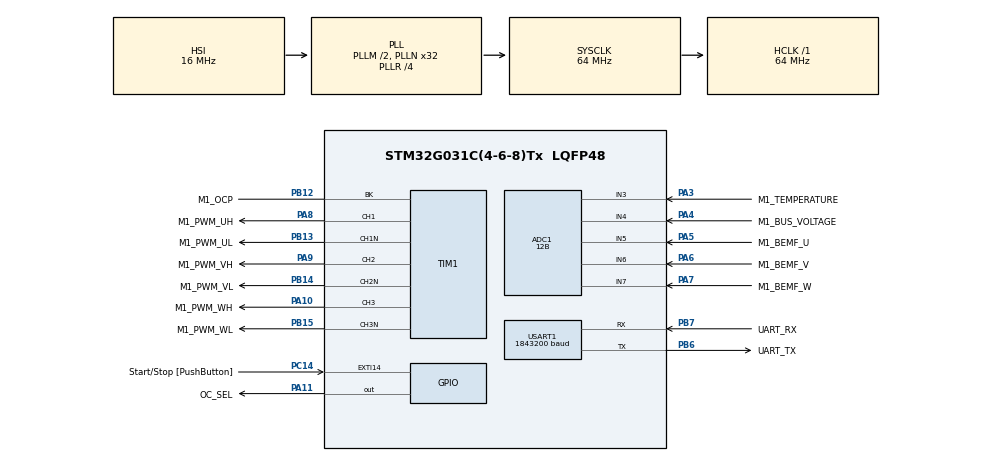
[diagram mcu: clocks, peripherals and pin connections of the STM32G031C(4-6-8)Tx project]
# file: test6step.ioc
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ADC1.ClockPrescaler=ADC_CLOCK_ASYNC_DIV1
ADC1.ContinuousConvMode=DISABLE
ADC1.DMAContinuousRequests=DISABLE
ADC1.DataAlign=ADC_DATAALIGN_LEFT
ADC1.DiscontinuousConvMode=DISABLE
ADC1.EOCSelection=ADC_EOC_SINGLE_CONV
ADC1.EnableAnalogWatchDog1=true
ADC1.ExternalTrigConv=ADC_EXTERNALTRIG_T1_TRGO2
ADC1.ExternalTrigConvEdge=ADC_EXTERNALTRIGCONVEDGE_FALLING
ADC1.LowPowerAutoPowerOff=DISABLE
ADC1.LowPowerAutoWait=DISABLE
ADC1.NbrOfConversion=1
ADC1.NbrOfConversionFlag=0
ADC1.Overrun=ADC_OVR_DATA_OVERWRITTEN
ADC1.OversamplingMode=DISABLE
ADC1.Resolution=ADC_RESOLUTION_12B
ADC1.SamplingTimeCommon1=ADC_SAMPLETIME_19CYCLES_5
ADC1.ScanConvMode=ADC_SCAN_SEQ_FIXED
ADC1.SelectedChannel=ADC_CHANNEL_3|ADC_CHANNEL_4|ADC_CHANNEL_5|ADC_CHANNEL_6|ADC_CHANNEL_7
ADC1.Sequencer=NOT_FULLY_CONFIGURABLE
ADC1.TriggerFrequencyMode=ADC_TRIGGER_FREQ_HIGH
ADC1.WatchdogChannel=ADC_CHANNEL_5
ADC1.WatchdogMode=ADC_ANALOGWATCHDOG_SINGLE_REG
ADC1.master=1
Dma.Request0=USART1_RX
Dma.Request1=USART1_TX
Dma.USART1_RX.0.Direction=DMA_PERIPH_TO_MEMORY
Dma.USART1_RX.0.EventEnable=DISABLE
Dma.USART1_RX.0.Instance=DMA1_Channel1
Dma.USART1_RX.0.MemDataAlignment=DMA_MDATAALIGN_BYTE
Dma.USART1_RX.0.MemInc=DMA_MINC_ENABLE
Dma.USART1_RX.0.Mode=DMA_NORMAL
Dma.USART1_RX.0.PeriphDataAlignment=DMA_PDATAALIGN_BYTE
Dma.USART1_RX.0.PeriphInc=DMA_PINC_DISABLE
Dma.USART1_RX.0.Polarity=HAL_DMAMUX_REQ_GEN_RISING
Dma.USART1_RX.0.Priority=DMA_PRIORITY_LOW
Dma.USART1_RX.0.RequestNumber=1
Dma.USART1_RX.0.SignalID=NONE
Dma.USART1_RX.0.SyncEnable=DISABLE
Dma.USART1_RX.0.SyncPolarity=HAL_DMAMUX_SYNC_NO_EVENT
Dma.USART1_RX.0.SyncRequestNumber=1
Dma.USART1_RX.0.SyncSignalID=NONE
Dma.USART1_TX.1.Direction=DMA_MEMORY_TO_PERIPH
Dma.USART1_TX.1.EventEnable=DISABLE
Dma.USART1_TX.1.Instance=DMA1_Channel2
Dma.USART1_TX.1.MemDataAlignment=DMA_MDATAALIGN_BYTE
Dma.USART1_TX.1.MemInc=DMA_MINC_ENABLE
Dma.USART1_TX.1.Mode=DMA_NORMAL
Dma.USART1_TX.1.PeriphDataAlignment=DMA_PDATAALIGN_BYTE
Dma.USART1_TX.1.PeriphInc=DMA_PINC_DISABLE
Dma.USART1_TX.1.Polarity=HAL_DMAMUX_REQ_GEN_RISING
Dma.USART1_TX.1.Priority=DMA_PRIORITY_LOW
Dma.USART1_TX.1.RequestNumber=1
Dma.USART1_TX.1.SignalID=NONE
Dma.USART1_TX.1.SyncEnable=DISABLE
Dma.USART1_TX.1.SyncPolarity=HAL_DMAMUX_SYNC_NO_EVENT
Dma.USART1_TX.1.SyncRequestNumber=1
Dma.USART1_TX.1.SyncSignalID=NONE
ExtraMW=MotorControl
ExtraMW.MotorControl.Config=MotorControl
ExtraMW.MotorControl.Mode=MotorControl
ExtraMW.MotorControl.Root=MCSDK_v6.4.1-Full/MotorControl
ExtraMW.MotorControl.Template=templates
Mcu.Family=STM32G0
Mcu.Name=STM32G031C(4-6-8)Tx
Mcu.Package=LQFP48
MotorControl.ADC_REFERENCE_VOLTAGE=3.3
MotorControl.BEMF_ADC_SAMPLING_TIME=19
MotorControl.BEMF_ADC_TRIG_TIME_DPP=921
MotorControl.BEMF_ADC_TRIG_TIME_ON_DPP=256
MotorControl.BEMF_AVERAGING_FIFO_DEPTH=8
MotorControl.BEMF_DIVIDER_AVAILABLE=false
MotorControl.BEMF_ON_SENSING_DIVIDER=14.691176
MotorControl.BEMF_PWM_ON_ENABLE_HYSTERESIS_DPP=51
MotorControl.BEMF_PWM_ON_ENABLE_THRES_DPP=716
MotorControl.BOARD=EVLSPIN32G0B1
MotorControl.BUS_VOLTAGE_READING=true
MotorControl.CCMRAM_ENABLED=false
MotorControl.CLOCK_FREQUENCY=CPU_CLK_64_MHZ
MotorControl.CLOCK_SOURCE=INTERNAL
MotorControl.CONFIG_OC_SEL=true
MotorControl.CPU_CLK_64_MHZ=true
MotorControl.CTLBOARD_NAME=EVLSPIN32G0B1
MotorControl.CUBE_MX_VER=6.16.1
MotorControl.CURR_REF_OC_SEL_GPIO_LABEL=OC_SEL
MotorControl.CURR_REF_OC_SEL_GPIO_PIN=LL_GPIO_PIN_11
MotorControl.CURR_REF_OC_SEL_GPIO_PORT=GPIOA
MotorControl.DBG_MCU_LOAD_MEASURE=false
MotorControl.DEBUG_DAC_FUNCTIONALITY_EN=false
MotorControl.DRIVES_NUMBER_SELECTION=SINGLEDRIVE
MotorControl.DRIVE_MODE=VM
MotorControl.DRIVE_NUMBER=1
MotorControl.DRIVE_TYPE=SIX_STEP
MotorControl.EMERGENCY_STOP_GPIO_PIN=LL_GPIO_PIN_12
MotorControl.EMERGENCY_STOP_GPIO_PORT=GPIOB
MotorControl.ENCODER_AVAILABLE=false
MotorControl.ENCODER_PPR=400
MotorControl.EXT_CLOCK_FREQUENCY=INT_RC_OSC
MotorControl.FAST_DEMAG=false
MotorControl.FLASH_SIZE=64
MotorControl.HALL_SENSORS_AVAILABLE=false
MotorControl.HIGH_SIDE_IDLE_STATE=false
MotorControl.HWV_OCP=SingleInput_RawCurrents_Protection_IntRef
MotorControl.HWV_PWM=PoweringHighAndLowSides
MotorControl.HW_COMPLEMENTED_LOW_SIDE=false
MotorControl.HW_DEAD_TIME_NS=700
MotorControl.INT_RC_OSC=true
MotorControl.IPs=SYS,NVIC,RCC,MotorControl,TIM1,TIM2,ADC1,USART1,DMA
MotorControl.LF_TIMER_SELECTION=LF_TIM2
MotorControl.LOW_MEMORY_FOOTPRINT_REG=false
MotorControl.LOW_SIDE_IDLE_STATE=false
MotorControl.LOW_SIDE_SIGNALS_ENABLING=LS_PWM_TIMER
MotorControl.M1_ADC_AWD_FILTER_NUMBER=0
MotorControl.M1_AUXILIARY_SPEED_SENSOR=NONE
MotorControl.M1_BEMF_THRESHOLD_PWM=50
MotorControl.M1_BEMF_THRESHOLD_PWM_HIGH=100
MotorControl.M1_BEMF_THRESHOLD_PWM_LOW=1
MotorControl.M1_BOARD_MAX_CURRENT=15
MotorControl.M1_BUS_VOLTAGE_READING=true
MotorControl.M1_COMPUTATION_DELAY=-2
MotorControl.M1_CURRENT_MONITOR_READING=false
MotorControl.M1_CUR_READING=false
MotorControl.M1_DBG_OPEN_LOOP_ENABLE=false
MotorControl.M1_DC_CURRENT_RS_MEAS=15
MotorControl.M1_DEFAULT_TARGET_SPEED_RPM=1000
MotorControl.M1_DP_TOPOLOGY=NONE
MotorControl.M1_DRIVE_TYPE=SIX_STEP
MotorControl.M1_ENABLE_SL_ALGO_FROM_PHASE=3
MotorControl.M1_ENCODER_PPR=400
MotorControl.M1_HALL_PHASE_SHIFT=300
MotorControl.M1_HALL_SENSORS_PLACEMENT=DEGREES_120
MotorControl.M1_HIGH_SIDE_IDLE_STATE=false
MotorControl.M1_HW_DEAD_TIME_NS=700
MotorControl.M1_ICL_ENABLED=false
MotorControl.M1_IPD_STARTUP=false
MotorControl.M1_LDLQ_RATIO=1.000
MotorControl.M1_LOW_SIDE_IDLE_STATE=false
MotorControl.M1_LOW_SIDE_SIGNALS_ENABLING=LS_PWM_TIMER
MotorControl.M1_LS=0.00002
MotorControl.M1_MAX_APPLICATION_SPEED=50000
MotorControl.M1_MAX_CONSECUTIVE_BEMF_ERRORS=3
MotorControl.M1_MIN_APPLICATION_SPEED=0
MotorControl.M1_MOTOR_MAX_SPEED_RPM=50000
MotorControl.M1_MOTOR_NAME=ECO III Series 2207
MotorControl.M1_MOTOR_RATED_FLUX=0.002099563
MotorControl.M1_MOTOR_VOLTAGE_CONSTANT=0.3
MotorControl.M1_NB_CONSECUTIVE_TESTS=10
MotorControl.M1_NOMINAL_BUS_VOLTAGE_V=17
MotorControl.M1_OBS_MINIMUM_SPEED_RPM=3000
MotorControl.M1_OCP_BKIN_FILTER=15
MotorControl.M1_OCP_BKIN_MODE=EXT_MODE
MotorControl.M1_OCP_BKIN_POLARITY=EMSTOP_ACTIVE_HIGH
MotorControl.M1_OCP_DESTINATION=TIM_BKIN
MotorControl.M1_OCP_TOPOLOGY=EXTERNAL
MotorControl.M1_ON_OVER_VOLTAGE=TURN_OFF_PWM
MotorControl.M1_OTF_STARTUP=false
MotorControl.M1_OVP_THRESHOLD_HIGH=20
MotorControl.M1_OV_TEMPERATURE_HYSTERESIS_C=10
MotorControl.M1_OV_TEMPERATURE_PROT_ENABLING=true
MotorControl.M1_OV_TEMPERATURE_THRESHOLD_C=90
MotorControl.M1_OV_VOLTAGE_PROT_ENABLING=true
MotorControl.M1_OV_VOLTAGE_THRESHOLD_V=20
MotorControl.M1_PHASE1_DURATION=500
MotorControl.M1_PHASE1_FINAL_SPEED_RPM=2000
MotorControl.M1_PHASE1_VOLTAGE_RMS=3.91
MotorControl.M1_PHASE2_DURATION=500
MotorControl.M1_PHASE2_FINAL_SPEED_RPM=2000
MotorControl.M1_PHASE2_VOLTAGE_RMS=3.91
MotorControl.M1_PHASE3_DURATION=500
MotorControl.M1_PHASE3_FINAL_SPEED_RPM=3000
MotorControl.M1_PHASE3_VOLTAGE_RMS=4.76
MotorControl.M1_PHASE4_DURATION=0
MotorControl.M1_PHASE4_FINAL_SPEED_RPM=0
MotorControl.M1_PHASE4_VOLTAGE_RMS=0.76
MotorControl.M1_PHASE5_DURATION=0
MotorControl.M1_PHASE5_FINAL_SPEED_RPM=0
MotorControl.M1_PHASE5_VOLTAGE_RMS=0.76
MotorControl.M1_PID_SPEED_KD_DEFAULT=0
MotorControl.M1_PID_SPEED_KI_DEFAULT=22
MotorControl.M1_PID_SPEED_KP_DEFAULT=177
MotorControl.M1_POLE_PAIR_NUM=7
MotorControl.M1_POTENTIOMETER_ENABLE=false
MotorControl.M1_POWERBOARD_NAME=EVLSPIN32G0B1
MotorControl.M1_PWM_CHARGE_BOOT_CAP_DUTY_CYCLES=0.000
MotorControl.M1_PWM_CHARGE_BOOT_CAP_MS=10
MotorControl.M1_PWM_DRIVER_PN=STSPIN32G0A1
MotorControl.M1_PWM_FREQUENCY=50000
MotorControl.M1_PWM_TIMER_BRK_IRQ=TIM1_BRK_UP_TRG_COM
MotorControl.M1_PWM_TIMER_SELECTION=PWM_TIM1
MotorControl.M1_PWM_TIMER_UP_IRQ=TIM1_BRK_UP_TRG_COM
MotorControl.M1_REGULATION_EXECUTION_RATE=1
MotorControl.M1_RS=0.05
MotorControl.M1_SHARED_SIGNAL_ENABLE=false
MotorControl.M1_SPD_DIFFERENTIAL_TERM_ENABLING=false
MotorControl.M1_SPEED_LOOP_FREQUENCY_HZ=10
MotorControl.M1_SPEED_SENSOR=SENSORLESS_ADC
MotorControl.M1_SP_KDDIV=16
MotorControl.M1_SP_KIDIV=16384
MotorControl.M1_SP_KPDIV=16384
MotorControl.M1_SS_MEAS_ERRORS_BEFORE_FAULTS=3
MotorControl.M1_STARTING_ANGLE_DEG=0
MotorControl.M1_SW_DEADTIME_NS=700
MotorControl.M1_T0_C=25
MotorControl.M1_TEMPERATURE_READING=true
MotorControl.M1_TEMP_ADC_SAMPLING_TIME=79
MotorControl.M1_TEMP_FDBK_ADC=ADC1
MotorControl.M1_TEMP_FDBK_CHANNEL=ADC_CHANNEL_3
MotorControl.M1_TRANSITION_DURATION=25
MotorControl.M1_T_MAX=90
MotorControl.M1_UD_VOLTAGE_THRESHOLD_V=12
MotorControl.M1_UV_VOLTAGE_PROT_ENABLING=true
MotorControl.M1_V0_V=0
MotorControl.M1_VBUS_ADC=ADC1
MotorControl.M1_VBUS_ADC_SAMPLING_TIME=79
MotorControl.M1_VBUS_CHANNEL=ADC_CHANNEL_4
MotorControl.M1_VBUS_PARTITIONING_FACTOR=0.05219206680584551
MotorControl.M1_ZCD_FALLING_TO_COMM=30
MotorControl.M1_ZCD_RISING_TO_COMM=30
MotorControl.M1_dV_dT=0.017
MotorControl.MCP_ASPEP_OVER_UART=true
MotorControl.MCP_ASYNC_EN=false
MotorControl.MCP_ASYNC_OVER_ASPEP_EN=false
MotorControl.MCP_ASYNC_OVER_UART_A_EN=false
MotorControl.MCP_DMACH_RX_UART_A=1
MotorControl.MCP_DMACH_TX_UART_A=2
MotorControl.MCP_DMA_RX_UART_A=DMA1
MotorControl.MCP_DMA_TX_UART_A=DMA1
MotorControl.MCP_EN=true
MotorControl.MCP_IRQ_HANDLER_DMA_RX_UART_A=DMA1_Channel1_IRQHandler
MotorControl.MCP_IRQ_HANDLER_UART_A=USART1_IRQHandler
MotorControl.MCP_OVER_ASPEP_EN=true
MotorControl.MCP_OVER_STLNK_EN=false
MotorControl.MCP_OVER_UART_A_EN=true
MotorControl.MCP_OVER_UART_B_EN=false
MotorControl.MCP_RX_SYNC_PAYLOAD_MAX=128
MotorControl.MCP_TX_SYNC_PAYLOAD_MAX=128
MotorControl.MCU=STSPIN32G0B1
MotorControl.MCU_FAMILY=STM32G0
MotorControl.MCU_LINE=STM32G0x1
MotorControl.MCU_NAME=STM32G031C(4-6-8)Tx
MotorControl.MCU_PACKAGE=LQFP48
MotorControl.MCU_TYPE=STSPIN32G0B1
MotorControl.MCU_USERNAME=STM32G031C8Tx
MotorControl.MC_WORKBENCH_VERSION=6.4.1
MotorControl.MIN_DEMAG_TIME=0
MotorControl.MOTOR_TYPE=PMSM
MotorControl.OCP_INT_REF=250
MotorControl.OCTH_STBY_GPIO=true
MotorControl.ON_OVER_VOLTAGE=TURN_OFF_PWM
MotorControl.OV_TEMPERATURE_PROT_ENABLING=true
MotorControl.OV_VOLTAGE_PROT_ENABLING=true
MotorControl.PHASE_UH_GPIO_PIN=LL_GPIO_PIN_8
MotorControl.PHASE_UH_GPIO_PORT=GPIOA
MotorControl.PHASE_UH_POLARITY=H_ACTIVE_HIGH
MotorControl.PHASE_UL_GPIO_PIN=LL_GPIO_PIN_13
MotorControl.PHASE_UL_GPIO_PORT=GPIOB
MotorControl.PHASE_UL_POLARITY=L_ACTIVE_HIGH
MotorControl.PHASE_U_BEMF_ADC=ADC1
MotorControl.PHASE_U_BEMF_CHANNEL=ADC_CHANNEL_5
MotorControl.PHASE_U_BEMF_GPIO_PIN=LL_GPIO_PIN_5
MotorControl.PHASE_U_BEMF_GPIO_PORT=GPIOA
MotorControl.PHASE_U_PWM_CHANNEL=TIM_Channel_1
MotorControl.PHASE_VH_GPIO_PIN=LL_GPIO_PIN_9
MotorControl.PHASE_VH_GPIO_PORT=GPIOA
MotorControl.PHASE_VH_POLARITY=H_ACTIVE_HIGH
MotorControl.PHASE_VL_GPIO_PIN=LL_GPIO_PIN_14
MotorControl.PHASE_VL_GPIO_PORT=GPIOB
MotorControl.PHASE_VL_POLARITY=L_ACTIVE_HIGH
MotorControl.PHASE_V_BEMF_ADC=ADC1
MotorControl.PHASE_V_BEMF_CHANNEL=ADC_CHANNEL_6
MotorControl.PHASE_V_BEMF_GPIO_PIN=LL_GPIO_PIN_6
MotorControl.PHASE_V_BEMF_GPIO_PORT=GPIOA
MotorControl.PHASE_V_PWM_CHANNEL=TIM_Channel_2
MotorControl.PHASE_WH_GPIO_PIN=LL_GPIO_PIN_10
MotorControl.PHASE_WH_GPIO_PORT=GPIOA
MotorControl.PHASE_WH_POLARITY=H_ACTIVE_HIGH
MotorControl.PHASE_WL_GPIO_PIN=LL_GPIO_PIN_15
MotorControl.PHASE_WL_GPIO_PORT=GPIOB
MotorControl.PHASE_WL_POLARITY=L_ACTIVE_HIGH
MotorControl.PHASE_W_BEMF_ADC=ADC1
MotorControl.PHASE_W_BEMF_CHANNEL=ADC_CHANNEL_7
MotorControl.PHASE_W_BEMF_GPIO_PIN=LL_GPIO_PIN_7
MotorControl.PHASE_W_BEMF_GPIO_PORT=GPIOA
MotorControl.PHASE_W_PWM_CHANNEL=TIM_Channel_3
MotorControl.POTENTIOMETER_READING=false
MotorControl.PWM_FREQUENCY=50000
MotorControl.PWM_TIMER_SELECTION=PWM_TIM1
MotorControl.QUASI_SYNC=false
MotorControl.REGULATION_EXECUTION_RATE=1
MotorControl.RUN_DEMAG_TIME=20
MotorControl.R_BRAKE_SWITCH_OFF_THRES_V=16
MotorControl.SENSORLESS_ADC=true
MotorControl.SINGLEDRIVE=true
MotorControl.SPD_DIFFERENTIAL_TERM_ENABLING=false
MotorControl.SPEED_SENSOR_SELECTION=SENSORLESS_ADC
MotorControl.SPEED_THRESHOLD_DEMAG=50000
MotorControl.STARTUP_DEMAG_TIME=20
MotorControl.START_STOP_BTN=true
MotorControl.START_STOP_GPIO_IRQ=EXTI4_15
MotorControl.START_STOP_GPIO_PIN=LL_GPIO_PIN_14
MotorControl.START_STOP_GPIO_PORT=GPIOC
MotorControl.START_STOP_POLARITY=DIN_ACTIVE_LOW
MotorControl.START_STOP_POLARITY_EDGE=GPIO_PULLUP
MotorControl.STSPIN32G0B1=true
MotorControl.SW_DEADTIME_NS=700
MotorControl.TEMPERATURE_READING=true
MotorControl.TEMP_ADC_SAMPLING_TIME=79
MotorControl.TEMP_FDBK_ADC=ADC1
MotorControl.TEMP_FDBK_CHANNEL=ADC_CHANNEL_3
MotorControl.TEMP_FDBK_GPIO_PIN=LL_GPIO_PIN_3
MotorControl.TEMP_FDBK_GPIO_PORT=GPIOA
MotorControl.TFDIFFERENTIAL_TERM_ENABLING=false
MotorControl.USART_RX_GPIO_PIN=LL_GPIO_PIN_7
MotorControl.USART_RX_GPIO_PORT=GPIOB
MotorControl.USART_SELECTION=USE_USART1
MotorControl.USART_SELECTION_A=USART1
MotorControl.USART_SPEED=1843200
MotorControl.USART_TX_GPIO_PIN=LL_GPIO_PIN_6
MotorControl.USART_TX_GPIO_PORT=GPIOB
MotorControl.UV_VOLTAGE_PROT_ENABLING=true
MotorControl.VBUS_ADC=ADC1
MotorControl.VBUS_ADC_SAMPLING_TIME=79
MotorControl.VBUS_CHANNEL=ADC_CHANNEL_4
MotorControl.VBUS_GPIO_PIN=LL_GPIO_PIN_4
MotorControl.VBUS_GPIO_PORT=GPIOA
MotorControl.WB_MX_ADC_AWD_FILTER_NUMBER=NONE
MotorControl.WB_MX_HEAPSIZE=0x200
MotorControl.WB_MX_PHASE_U_BEMF_ADC_IRQ=ADC1
MotorControl.WB_MX_PHASE_V_BEMF_ADC_IRQ=ADC1
MotorControl.WB_MX_PHASE_W_BEMF_ADC_IRQ=ADC1
MotorControl.WB_MX_STACKSIZE=0x400
MotorControl.WB_MX_TRUSTZONE_AVAILABLE=false
MotorControl.WB_UI_ENCODER_HAS_INDEX_PIN=false
MotorControl.WB_UI_FRICTION=0.437
MotorControl.WB_UI_INERTIA=0.348
MotorControl.WB_UI_MAGNETIC_STRUCTURE=SM-PMSM
MotorControl.WB_UI_MAX_CURRENT=15
MotorControl.WB_UI_MAX_NOMINAL_DC_VOLTAGE=17
MotorControl.WB_UI_MAX_PWMFREQUENCY=50000
MotorControl.WB_UI_MOTOR_DESCRIPTION=External rotor type - 7 poles pairs brushless - DC motor
MotorControl.WB_UI_OCP_SINGLEINPUT_INDEPENDENT_WIRES={'CURRENT_INPUT_P'\:{'ip'\:'COMP0','pin'\:'OC_Comp','peripheral'\:'COMP0_INP','help'\:'','cost'\:0}}
MotorControl.WB_UI_OCP_SINGLE_INPUT_GAIN=0.01
MotorControl.WB_UI_OCP_SINGLE_INPUT_OFFSET=0.012
MotorControl.WB_UI_OCP_THRESHOLD=23.8
MotorControl.WB_UI_PWM_ON_SENSING=true
MotorControl.WB_UI_PW_BOARD_MAX_RATED_CURRENT=15
MotorControl.WB_UI_PW_BOARD_MAX_VOLTAGE=45
MotorControl.WB_UI_PW_BOARD_MIN_VOLTAGE=7
MotorControl.WB_to_Mx_template_version=25-05-06
MotorControl.WB_to_Mx_version=6.4.1-RC1-Full
NVIC.ADC1_IRQn=true\:0\:0\:true\:true\:false\:5\:true\:true\:true
NVIC.DMA1_Channel1_IRQn=true\:3\:0\:true\:true\:false\:2\:true\:true\:true
NVIC.EXTI4_15_IRQn=true\:3\:0\:false\:true\:false\:6\:true\:true\:true
NVIC.TIM1_BRK_UP_TRG_COM_IRQn=true\:0\:0\:false\:true\:false\:4\:true\:true\:true
NVIC.TIM2_IRQn=true\:0\:0\:true\:true\:false\:3\:true\:true\:true
NVIC.USART1_IRQn=true\:3\:0\:true\:true\:false\:1\:true\:true\:true
PA10.GPIO_Label=M1_PWM_WH
PA10.GPIO_PuPd=GPIO_PULLDOWN
PA10.GPIO_Speed=GPIO_SPEED_FREQ_HIGH
PA10.Signal=S_TIM1_CH3
PA11\ [PA9].GPIO_Label=OC_SEL
PA11\ [PA9].GPIO_PuPd=GPIO_PULLDOWN
PA11\ [PA9].PinState=GPIO_PIN_SET
PA11\ [PA9].Signal=GPIO_Output
PA13.GPIO_Label=TMS
PA13.Mode=Serial_Wire
PA13.Signal=SYS_SWDIO
PA14-BOOT0.GPIO_Label=TCK
PA14-BOOT0.Mode=Serial_Wire
PA14-BOOT0.Signal=SYS_SWCLK
PA3.GPIO_Label=M1_TEMPERATURE
PA3.Mode=IN3
PA3.Signal=ADC1_IN3
PA4.GPIO_Label=M1_BUS_VOLTAGE
PA4.Mode=IN4
PA4.Signal=ADC1_IN4
PA5.GPIO_Label=M1_BEMF_U
PA5.Mode=IN5
PA5.Signal=ADC1_IN5
PA6.GPIO_Label=M1_BEMF_V
PA6.Mode=IN6
PA6.Signal=ADC1_IN6
PA7.GPIO_Label=M1_BEMF_W
PA7.Mode=IN7
PA7.Signal=ADC1_IN7
PA8.GPIO_Label=M1_PWM_UH
PA8.GPIO_PuPd=GPIO_PULLDOWN
PA8.GPIO_Speed=GPIO_SPEED_FREQ_HIGH
PA8.Signal=S_TIM1_CH1
PA9.GPIO_Label=M1_PWM_VH
PA9.GPIO_PuPd=GPIO_PULLDOWN
PA9.GPIO_Speed=GPIO_SPEED_FREQ_HIGH
PA9.Signal=S_TIM1_CH2
PB12.GPIO_Label=M1_OCP
PB12.GPIO_PuPd=GPIO_PULLDOWN
PB12.Mode=Activate-Break-Input
PB12.Signal=TIM1_BK
PB13.GPIO_Label=M1_PWM_UL
PB13.GPIO_PuPd=GPIO_PULLDOWN
PB13.GPIO_Speed=GPIO_SPEED_FREQ_HIGH
PB13.Mode=PWM Generation1 CH1 CH1N
PB13.Signal=TIM1_CH1N
PB14.GPIO_Label=M1_PWM_VL
PB14.GPIO_PuPd=GPIO_PULLDOWN
PB14.GPIO_Speed=GPIO_SPEED_FREQ_HIGH
PB14.Mode=PWM Generation2 CH2 CH2N
PB14.Signal=TIM1_CH2N
PB15.GPIO_Label=M1_PWM_WL
PB15.GPIO_PuPd=GPIO_PULLDOWN
PB15.GPIO_Speed=GPIO_SPEED_FREQ_HIGH
PB15.Mode=PWM Generation3 CH3 CH3N
PB15.Signal=TIM1_CH3N
PB6.GPIO_Label=UART_TX
PB6.GPIO_Mode=GPIO_MODE_AF_PP
PB6.GPIO_PuPd=GPIO_NOPULL
PB6.GPIO_Speed=GPIO_SPEED_FREQ_LOW
PB6.Mode=Asynchronous
PB6.Signal=USART1_TX
PB7.GPIO_Label=UART_RX
PB7.GPIO_Mode=GPIO_MODE_AF_PP
PB7.GPIO_PuPd=GPIO_NOPULL
PB7.GPIO_Speed=GPIO_SPEED_FREQ_LOW
PB7.Mode=Asynchronous
PB7.Signal=USART1_RX
PC14-OSC32_IN\ (PC14).GPIO_Label=Start/Stop [PushButton]
PC14-OSC32_IN\ (PC14).GPIO_ModeDefaultEXTI=GPIO_MODE_IT_FALLING
PC14-OSC32_IN\ (PC14).GPIO_PuPd=GPIO_PULLUP
PC14-OSC32_IN\ (PC14).Signal=GPXTI14
ProjectManager.HeapSize=0x200
ProjectManager.StackSize=0x400
ProjectManager.TargetToolchain=STM32CubeIDE
RCC.ADCCLockSelection=RCC_ADCCLKSOURCE_PLLADC
RCC.ADCFreq_Value=32000000
RCC.AHBFreq_Value=64000000
RCC.CortexFreq_Value=64000000
RCC.EXTERNAL_CLOCK_VALUE=12288000
RCC.HCLKFreq_Value=64000000
RCC.HSE_VALUE=8000000
RCC.HSI_VALUE=16000000
RCC.LSE_VALUE=32768
RCC.PLLM=RCC_PLLM_DIV2
RCC.PLLN=32
RCC.PLLP=RCC_PLLP_DIV8
RCC.PLLQ=RCC_PLLQ_DIV2
RCC.PLLR=RCC_PLLR_DIV4
RCC.PLLSourceVirtual=RCC_PLLSOURCE_HSI
RCC.PREFETCH_ENABLE=1
RCC.SYSCLKFreq_VALUE=64000000
RCC.SYSCLKSource=RCC_SYSCLKSOURCE_PLLCLK
RCC.TIM1CLockSelectionVirtual=RCC_TIM1CLKSOURCE_PLL
RCC.VCOOutputFreq_Value=256000000
SH.S_TIM1_CH1.0=TIM1_CH1,PWM Generation1 CH1 CH1N
SH.S_TIM1_CH2.0=TIM1_CH2,PWM Generation2 CH2 CH2N
SH.S_TIM1_CH3.0=TIM1_CH3,PWM Generation3 CH3 CH3N
TIM1.AutoReloadPreload=TIM_AUTORELOAD_PRELOAD_DISABLE
TIM1.AutomaticOutput=TIM_AUTOMATICOUTPUT_DISABLE
TIM1.Break2Filter=3
TIM1.Break2Polarity=TIM_BREAK2POLARITY_HIGH
TIM1.Break2State=TIM_BREAK2_DISABLE
TIM1.BreakAFMode=TIM_BREAK_AFMODE_INPUT
TIM1.BreakFilter=15
TIM1.BreakPolarity=TIM_BREAKPOLARITY_HIGH
TIM1.BreakState=TIM_BREAK_ENABLE
TIM1.Channel=TIM_CHANNEL_4
TIM1.Channel-PWM\ Generation1\ CH1\ CH1N=TIM_CHANNEL_1
TIM1.Channel-PWM\ Generation2\ CH2\ CH2N=TIM_CHANNEL_2
TIM1.Channel-PWM\ Generation3\ CH3\ CH3N=TIM_CHANNEL_3
TIM1.Channel-PWM\ Generation4\ No\ Output=TIM_CHANNEL_4
TIM1.ClearInputSource=TIM_CLEARINPUTSOURCE_NONE
TIM1.ClockDivision=TIM_CLOCKDIVISION_DIV1
TIM1.CounterMode=TIM_COUNTERMODE_UP
TIM1.DeadTime=((DEAD_TIME_COUNTS) / 2)
TIM1.LockLevel=TIM_LOCKLEVEL_OFF
TIM1.OC1Preload_PWM=ENABLE
TIM1.OC2Preload_PWM=ENABLE
TIM1.OC3Preload_PWM=ENABLE
TIM1.OC4Preload_PWM=ENABLE
TIM1.OCFastMode_PWM=TIM_OCFAST_DISABLE
TIM1.OCIdleState_1=TIM_OCIDLESTATE_RESET
TIM1.OCIdleState_2=TIM_OCIDLESTATE_RESET
TIM1.OCIdleState_3=TIM_OCIDLESTATE_RESET
TIM1.OCIdleState_4=TIM_OCIDLESTATE_RESET
TIM1.OCMode_PWM-PWM\ Generation1\ CH1\ CH1N=TIM_OCMODE_PWM1
TIM1.OCMode_PWM-PWM\ Generation2\ CH2\ CH2N=TIM_OCMODE_PWM1
TIM1.OCMode_PWM-PWM\ Generation3\ CH3\ CH3N=TIM_OCMODE_PWM1
TIM1.OCMode_PWM-PWM\ Generation4\ No\ Output=TIM_OCMODE_PWM1
TIM1.OCNIdleState_1=TIM_OCNIDLESTATE_RESET
TIM1.OCNIdleState_2=TIM_OCNIDLESTATE_RESET
TIM1.OCNIdleState_3=TIM_OCNIDLESTATE_RESET
TIM1.OCNPolarity_1=TIM_OCNPOLARITY_HIGH
TIM1.OCNPolarity_2=TIM_OCNPOLARITY_HIGH
TIM1.OCNPolarity_3=TIM_OCNPOLARITY_HIGH
TIM1.OCPolarity_1=TIM_OCPOLARITY_HIGH
TIM1.OCPolarity_2=TIM_OCPOLARITY_HIGH
TIM1.OCPolarity_3=TIM_OCPOLARITY_HIGH
TIM1.OCPolarity_4=TIM_OCPOLARITY_HIGH
TIM1.OffStateIDLEMode=TIM_OSSI_ENABLE
TIM1.OffStateRunMode=TIM_OSSR_ENABLE
TIM1.Period=(PWM_PERIOD_CYCLES)
TIM1.Prescaler=((TIM_CLOCK_DIVIDER) - 1)
TIM1.RepetitionCounter=(REP_COUNTER)
TIM1.SourceBRK2DigInput=TIM_BREAKINPUTSOURCE_DISABLE
TIM1.SourceBRKDigInput=TIM_BREAKINPUTSOURCE_ENABLE
TIM1.SourceBRKDigInputPolarity=TIM_BREAKINPUTSOURCE_POLARITY_HIGH
TIM1.TIM_MasterOutputTrigger=TIM_TRGO_RESET
TIM1.TIM_MasterOutputTrigger2=TIM_TRGO2_OC4REF
TIM1.TIM_MasterSlaveMode=TIM_MASTERSLAVEMODE_ENABLE
TIM2.Period=LF_TIMER_ARR
TIM2.Prescaler=LF_TIMER_PSC
TIM2.TIM_MasterOutputTrigger=TIM_TRGO_ENABLE
TIM2.TIM_MasterSlaveMode=TIM_MASTERSLAVEMODE_ENABLE
USART1.BaudRate=1843200
USART1.VirtualMode-Asynchronous=VM_ASYNC
USART1.WordLength=WORDLENGTH_8B
VP_MotorControl_MC_ENABLED.Mode=SixStep
VP_TIM1_VS_ClockSourceINT.Mode=Internal
VP_TIM1_VS_no_output4.Mode=PWM Generation4 No Output
VP_TIM2_VS_ClockSourceINT.Mode=Internal
board=custom

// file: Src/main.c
/* USER CODE BEGIN Header */
/**
  ******************************************************************************
  * @file           : main.c
  * @brief          : Main program body
  ******************************************************************************
  * @attention
  *
  * Copyright (c) 2026 STMicroelectronics.
  * All rights reserved.
  *
  * This software is licensed under terms that can be found in the LICENSE file
  * in the root directory of this software component.
  * If no LICENSE file comes with this software, it is provided AS-IS.
  *
  ******************************************************************************
  */
/* USER CODE END Header */
#include "main.h"

/* USER CODE BEGIN Includes */
#include "pid_regulator.h"
/* USER CODE END Includes */

ADC_HandleTypeDef hadc1;

TIM_HandleTypeDef htim1;
TIM_HandleTypeDef htim2;

UART_HandleTypeDef huart1;
DMA_HandleTypeDef hdma_usart1_rx;
DMA_HandleTypeDef hdma_usart1_tx;

void SystemClock_Config(void);
static void MX_GPIO_Init(void);
static void MX_DMA_Init(void);
static void MX_ADC1_Init(void);
static void MX_TIM1_Init(void);
static void MX_TIM2_Init(void);
static void MX_USART1_UART_Init(void);
static void MX_NVIC_Init(void);

int main(void)
{

  /* MCU Configuration--------------------------------------------------------*/

  /* Reset of all peripherals, Initializes the Flash interface and the Systick. */
  HAL_Init();

  /* Configure the system clock */
  SystemClock_Config();

  /* Initialize all configured peripherals */
  MX_GPIO_Init();
  MX_DMA_Init();
  MX_ADC1_Init();
  MX_TIM1_Init();
  MX_TIM2_Init();
  MX_USART1_UART_Init();
  MX_MotorControl_Init();

  /* Initialize interrupts */
  MX_NVIC_Init();

  /* Infinite loop */
  while (1)
  {

  }
}

void SystemClock_Config(void)
{
  RCC_OscInitTypeDef RCC_OscInitStruct = {0};
  RCC_ClkInitTypeDef RCC_ClkInitStruct = {0};

  /** Configure the main internal regulator output voltage
  */
  HAL_PWREx_ControlVoltageScaling(PWR_REGULATOR_VOLTAGE_SCALE1);

  /** Initializes the RCC Oscillators according to the specified parameters
  * in the RCC_OscInitTypeDef structure.
  */
  RCC_OscInitStruct.OscillatorType = RCC_OSCILLATORTYPE_HSI;
  RCC_OscInitStruct.HSIState = RCC_HSI_ON;
  RCC_OscInitStruct.HSIDiv = RCC_HSI_DIV1;
  RCC_OscInitStruct.HSICalibrationValue = RCC_HSICALIBRATION_DEFAULT;
  RCC_OscInitStruct.PLL.PLLState = RCC_PLL_ON;
  RCC_OscInitStruct.PLL.PLLSource = RCC_PLLSOURCE_HSI;
  RCC_OscInitStruct.PLL.PLLM = RCC_PLLM_DIV2;
  RCC_OscInitStruct.PLL.PLLN = 32;
  RCC_OscInitStruct.PLL.PLLP = RCC_PLLP_DIV8;
  RCC_OscInitStruct.PLL.PLLQ = RCC_PLLQ_DIV2;
  RCC_OscInitStruct.PLL.PLLR = RCC_PLLR_DIV4;
  if (HAL_RCC_OscConfig(&RCC_OscInitStruct) != HAL_OK)
  {
    Error_Handler();
  }

  /** Initializes the CPU, AHB and APB buses clocks
  */
  RCC_ClkInitStruct.ClockType = RCC_CLOCKTYPE_HCLK|RCC_CLOCKTYPE_SYSCLK
                              |RCC_CLOCKTYPE_PCLK1;
  RCC_ClkInitStruct.SYSCLKSource = RCC_SYSCLKSOURCE_PLLCLK;
  RCC_ClkInitStruct.AHBCLKDivider = RCC_SYSCLK_DIV1;
  RCC_ClkInitStruct.APB1CLKDivider = RCC_HCLK_DIV1;

  if (HAL_RCC_ClockConfig(&RCC_ClkInitStruct, FLASH_LATENCY_2) != HAL_OK)
  {
    Error_Handler();
  }
}

/**
  * @brief NVIC Configuration.
  * @retval None
  */
static void MX_NVIC_Init(void)
{
  /* USART1_IRQn interrupt configuration */
  HAL_NVIC_SetPriority(USART1_IRQn, 3, 0);
  HAL_NVIC_EnableIRQ(USART1_IRQn);
  /* DMA1_Channel1_IRQn interrupt configuration */
  HAL_NVIC_SetPriority(DMA1_Channel1_IRQn, 3, 0);
  HAL_NVIC_EnableIRQ(DMA1_Channel1_IRQn);
  /* TIM2_IRQn interrupt configuration */
  HAL_NVIC_SetPriority(TIM2_IRQn, 0, 0);
  HAL_NVIC_EnableIRQ(TIM2_IRQn);
  /* TIM1_BRK_UP_TRG_COM_IRQn interrupt configuration */
  HAL_NVIC_SetPriority(TIM1_BRK_UP_TRG_COM_IRQn, 0, 0);
  HAL_NVIC_EnableIRQ(TIM1_BRK_UP_TRG_COM_IRQn);
  /* ADC1_IRQn interrupt configuration */
  HAL_NVIC_SetPriority(ADC1_IRQn, 0, 0);
  HAL_NVIC_EnableIRQ(ADC1_IRQn);
  /* EXTI4_15_IRQn interrupt configuration */
  HAL_NVIC_SetPriority(EXTI4_15_IRQn, 3, 0);
  HAL_NVIC_EnableIRQ(EXTI4_15_IRQn);
}

static void MX_ADC1_Init(void)
{

  ADC_ChannelConfTypeDef sConfig = {0};
  ADC_AnalogWDGConfTypeDef AnalogWDGConfig = {0};

  /** Configure the global features of the ADC (Clock, Resolution, Data Alignment and number of conversion)
  */
  hadc1.Instance = ADC1;
  hadc1.Init.ClockPrescaler = ADC_CLOCK_ASYNC_DIV1;
  hadc1.Init.Resolution = ADC_RESOLUTION_12B;
  hadc1.Init.DataAlign = ADC_DATAALIGN_LEFT;
  hadc1.Init.ScanConvMode = ADC_SCAN_SEQ_FIXED;
  hadc1.Init.EOCSelection = ADC_EOC_SINGLE_CONV;
  hadc1.Init.LowPowerAutoWait = DISABLE;
  hadc1.Init.LowPowerAutoPowerOff = DISABLE;
  hadc1.Init.ContinuousConvMode = DISABLE;
  hadc1.Init.NbrOfConversion = 1;
  hadc1.Init.DiscontinuousConvMode = DISABLE;
  hadc1.Init.ExternalTrigConv = ADC_EXTERNALTRIG_T1_TRGO2;
  hadc1.Init.ExternalTrigConvEdge = ADC_EXTERNALTRIGCONVEDGE_FALLING;
  hadc1.Init.DMAContinuousRequests = DISABLE;
  hadc1.Init.Overrun = ADC_OVR_DATA_OVERWRITTEN;
  hadc1.Init.SamplingTimeCommon1 = ADC_SAMPLETIME_19CYCLES_5;
  hadc1.Init.OversamplingMode = DISABLE;
  hadc1.Init.TriggerFrequencyMode = ADC_TRIGGER_FREQ_HIGH;
  if (HAL_ADC_Init(&hadc1) != HAL_OK)
  {
    Error_Handler();
  }

  /** Configure Regular Channel
  */
  sConfig.Channel = ADC_CHANNEL_3;
  sConfig.Rank = ADC_RANK_CHANNEL_NUMBER;
  if (HAL_ADC_ConfigChannel(&hadc1, &sConfig) != HAL_OK)
  {
    Error_Handler();
  }

  /** Configure Regular Channel
  */
  sConfig.Channel = ADC_CHANNEL_4;
  if (HAL_ADC_ConfigChannel(&hadc1, &sConfig) != HAL_OK)
  {
    Error_Handler();
  }

  /** Configure Regular Channel
  */
  sConfig.Channel = ADC_CHANNEL_5;
  if (HAL_ADC_ConfigChannel(&hadc1, &sConfig) != HAL_OK)
  {
    Error_Handler();
  }

  /** Configure Regular Channel
  */
  sConfig.Channel = ADC_CHANNEL_6;
  if (HAL_ADC_ConfigChannel(&hadc1, &sConfig) != HAL_OK)
  {
    Error_Handler();
  }

  /** Configure Regular Channel
  */
  sConfig.Channel = ADC_CHANNEL_7;
  if (HAL_ADC_ConfigChannel(&hadc1, &sConfig) != HAL_OK)
  {
    Error_Handler();
  }

  /** Configure Analog WatchDog 1
  */
  AnalogWDGConfig.WatchdogNumber = ADC_ANALOGWATCHDOG_1;
  AnalogWDGConfig.WatchdogMode = ADC_ANALOGWATCHDOG_SINGLE_REG;
  AnalogWDGConfig.Channel = ADC_CHANNEL_3;
  AnalogWDGConfig.ITMode = DISABLE;
  AnalogWDGConfig.HighThreshold = 0;
  AnalogWDGConfig.LowThreshold = 0;
  if (HAL_ADC_AnalogWDGConfig(&hadc1, &AnalogWDGConfig) != HAL_OK)
  {
    Error_Handler();
  }

}

static void MX_TIM1_Init(void)
{

  TIM_ClockConfigTypeDef sClockSourceConfig = {0};
  TIM_MasterConfigTypeDef sMasterConfig = {0};
  TIMEx_BreakInputConfigTypeDef sBreakInputConfig = {0};
  TIM_OC_InitTypeDef sConfigOC = {0};
  TIM_BreakDeadTimeConfigTypeDef sBreakDeadTimeConfig = {0};

  htim1.Instance = TIM1;
  htim1.Init.Prescaler = ((TIM_CLOCK_DIVIDER) - 1);
  htim1.Init.CounterMode = TIM_COUNTERMODE_UP;
  htim1.Init.Period = (PWM_PERIOD_CYCLES);
  htim1.Init.ClockDivision = TIM_CLOCKDIVISION_DIV1;
  htim1.Init.RepetitionCounter = (REP_COUNTER);
  htim1.Init.AutoReloadPreload = TIM_AUTORELOAD_PRELOAD_DISABLE;
  if (HAL_TIM_Base_Init(&htim1) != HAL_OK)
  {
    Error_Handler();
  }
  sClockSourceConfig.ClockSource = TIM_CLOCKSOURCE_INTERNAL;
  if (HAL_TIM_ConfigClockSource(&htim1, &sClockSourceConfig) != HAL_OK)
  {
    Error_Handler();
  }
  if (HAL_TIM_PWM_Init(&htim1) != HAL_OK)
  {
    Error_Handler();
  }
  sMasterConfig.MasterOutputTrigger = TIM_TRGO_RESET;
  sMasterConfig.MasterOutputTrigger2 = TIM_TRGO2_OC4REF;
  sMasterConfig.MasterSlaveMode = TIM_MASTERSLAVEMODE_ENABLE;
  if (HAL_TIMEx_MasterConfigSynchronization(&htim1, &sMasterConfig) != HAL_OK)
  {
    Error_Handler();
  }
  sBreakInputConfig.Source = TIM_BREAKINPUTSOURCE_BKIN;
  sBreakInputConfig.Enable = TIM_BREAKINPUTSOURCE_ENABLE;
  sBreakInputConfig.Polarity = TIM_BREAKINPUTSOURCE_POLARITY_HIGH;
  if (HAL_TIMEx_ConfigBreakInput(&htim1, TIM_BREAKINPUT_BRK, &sBreakInputConfig) != HAL_OK)
  {
    Error_Handler();
  }
  sConfigOC.OCMode = TIM_OCMODE_PWM1;
  sConfigOC.Pulse = 0;
  sConfigOC.OCPolarity = TIM_OCPOLARITY_HIGH;
  sConfigOC.OCNPolarity = TIM_OCNPOLARITY_HIGH;
  sConfigOC.OCFastMode = TIM_OCFAST_DISABLE;
  sConfigOC.OCIdleState = TIM_OCIDLESTATE_RESET;
  sConfigOC.OCNIdleState = TIM_OCNIDLESTATE_RESET;
  if (HAL_TIM_PWM_ConfigChannel(&htim1, &sConfigOC, TIM_CHANNEL_1) != HAL_OK)
  {
    Error_Handler();
  }
  if (HAL_TIM_PWM_ConfigChannel(&htim1, &sConfigOC, TIM_CHANNEL_2) != HAL_OK)
  {
    Error_Handler();
  }
  if (HAL_TIM_PWM_ConfigChannel(&htim1, &sConfigOC, TIM_CHANNEL_3) != HAL_OK)
  {
    Error_Handler();
  }
  if (HAL_TIM_PWM_ConfigChannel(&htim1, &sConfigOC, TIM_CHANNEL_4) != HAL_OK)
  {
    Error_Handler();
  }
  sBreakDeadTimeConfig.OffStateRunMode = TIM_OSSR_ENABLE;
  sBreakDeadTimeConfig.OffStateIDLEMode = TIM_OSSI_ENABLE;
  sBreakDeadTimeConfig.LockLevel = TIM_LOCKLEVEL_OFF;
  sBreakDeadTimeConfig.DeadTime = ((DEAD_TIME_COUNTS) / 2);
  sBreakDeadTimeConfig.BreakState = TIM_BREAK_ENABLE;
  sBreakDeadTimeConfig.BreakPolarity = TIM_BREAKPOLARITY_HIGH;
  sBreakDeadTimeConfig.BreakFilter = 15;
  sBreakDeadTimeConfig.BreakAFMode = TIM_BREAK_AFMODE_INPUT;
  sBreakDeadTimeConfig.Break2State = TIM_BREAK2_DISABLE;
  sBreakDeadTimeConfig.Break2Polarity = TIM_BREAK2POLARITY_HIGH;
  sBreakDeadTimeConfig.Break2Filter = 3;
  sBreakDeadTimeConfig.Break2AFMode = TIM_BREAK_AFMODE_INPUT;
  sBreakDeadTimeConfig.AutomaticOutput = TIM_AUTOMATICOUTPUT_DISABLE;
  if (HAL_TIMEx_ConfigBreakDeadTime(&htim1, &sBreakDeadTimeConfig) != HAL_OK)
  {
    Error_Handler();
  }
  HAL_TIM_MspPostInit(&htim1);

}

static void MX_TIM2_Init(void)
{

  TIM_ClockConfigTypeDef sClockSourceConfig = {0};
  TIM_MasterConfigTypeDef sMasterConfig = {0};

  htim2.Instance = TIM2;
  htim2.Init.Prescaler = LF_TIMER_PSC;
  htim2.Init.CounterMode = TIM_COUNTERMODE_UP;
  htim2.Init.Period = LF_TIMER_ARR;
  htim2.Init.ClockDivision = TIM_CLOCKDIVISION_DIV1;
  htim2.Init.AutoReloadPreload = TIM_AUTORELOAD_PRELOAD_DISABLE;
  if (HAL_TIM_Base_Init(&htim2) != HAL_OK)
  {
    Error_Handler();
  }
  sClockSourceConfig.ClockSource = TIM_CLOCKSOURCE_INTERNAL;
  if (HAL_TIM_ConfigClockSource(&htim2, &sClockSourceConfig) != HAL_OK)
  {
    Error_Handler();
  }
  sMasterConfig.MasterOutputTrigger = TIM_TRGO_ENABLE;
  sMasterConfig.MasterSlaveMode = TIM_MASTERSLAVEMODE_ENABLE;
  if (HAL_TIMEx_MasterConfigSynchronization(&htim2, &sMasterConfig) != HAL_OK)
  {
    Error_Handler();
  }

}

static void MX_USART1_UART_Init(void)
{

  huart1.Instance = USART1;
  huart1.Init.BaudRate = 1843200;
  huart1.Init.WordLength = UART_WORDLENGTH_8B;
  huart1.Init.StopBits = UART_STOPBITS_1;
  huart1.Init.Parity = UART_PARITY_NONE;
  huart1.Init.Mode = UART_MODE_TX_RX;
  huart1.Init.HwFlowCtl = UART_HWCONTROL_NONE;
  huart1.Init.OverSampling = UART_OVERSAMPLING_16;
  huart1.Init.OneBitSampling = UART_ONE_BIT_SAMPLE_DISABLE;
  huart1.Init.ClockPrescaler = UART_PRESCALER_DIV1;
  huart1.AdvancedInit.AdvFeatureInit = UART_ADVFEATURE_NO_INIT;
  if (HAL_UART_Init(&huart1) != HAL_OK)
  {
    Error_Handler();
  }
  if (HAL_UARTEx_SetTxFifoThreshold(&huart1, UART_TXFIFO_THRESHOLD_1_8) != HAL_OK)
  {
    Error_Handler();
  }
  if (HAL_UARTEx_SetRxFifoThreshold(&huart1, UART_RXFIFO_THRESHOLD_1_8) != HAL_OK)
  {
    Error_Handler();
  }
  if (HAL_UARTEx_DisableFifoMode(&huart1) != HAL_OK)
  {
    Error_Handler();
  }

}

static void MX_DMA_Init(void)
{

  /* DMA controller clock enable */
  __HAL_RCC_DMA1_CLK_ENABLE();

}

static void MX_GPIO_Init(void)
{
  GPIO_InitTypeDef GPIO_InitStruct = {0};

  /* GPIO Ports Clock Enable */
  __HAL_RCC_GPIOC_CLK_ENABLE();
  __HAL_RCC_GPIOA_CLK_ENABLE();
  __HAL_RCC_GPIOB_CLK_ENABLE();

  /*Configure GPIO pin Output Level */
  HAL_GPIO_WritePin(OC_SEL_GPIO_Port, OC_SEL_Pin, GPIO_PIN_SET);

  /*Configure GPIO pin : Start_Stop_Pin */
  GPIO_InitStruct.Pin = Start_Stop_Pin;
  GPIO_InitStruct.Mode = GPIO_MODE_IT_FALLING;
  GPIO_InitStruct.Pull = GPIO_PULLUP;
  HAL_GPIO_Init(Start_Stop_GPIO_Port, &GPIO_InitStruct);

  /*Configure GPIO pin : OC_SEL_Pin */
  GPIO_InitStruct.Pin = OC_SEL_Pin;
  GPIO_InitStruct.Mode = GPIO_MODE_OUTPUT_PP;
  GPIO_InitStruct.Pull = GPIO_PULLDOWN;
  GPIO_InitStruct.Speed = GPIO_SPEED_FREQ_LOW;
  HAL_GPIO_Init(OC_SEL_GPIO_Port, &GPIO_InitStruct);

}

void Error_Handler(void)
{
  __disable_irq();
  while (1)
  {
  }
}
